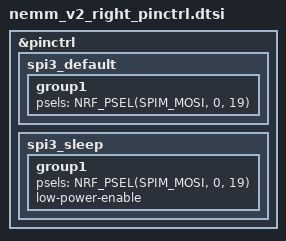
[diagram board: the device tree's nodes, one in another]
/*
# Copyright (c) 2021 The ZMK Contributors
*
* SPDX-License-Identifier: MIT
*/
#include <dt-bindings/led/led.h>

&pinctrl {
	spi3_default: spi3_default {
        group1 {
            psels = <NRF_PSEL(SPIM_MOSI, 0, 19)>;
        };
    };

    spi3_sleep: spi3_sleep {
        group1 {
            psels = <NRF_PSEL(SPIM_MOSI, 0, 19)>;
            low-power-enable;
        };
    };
};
